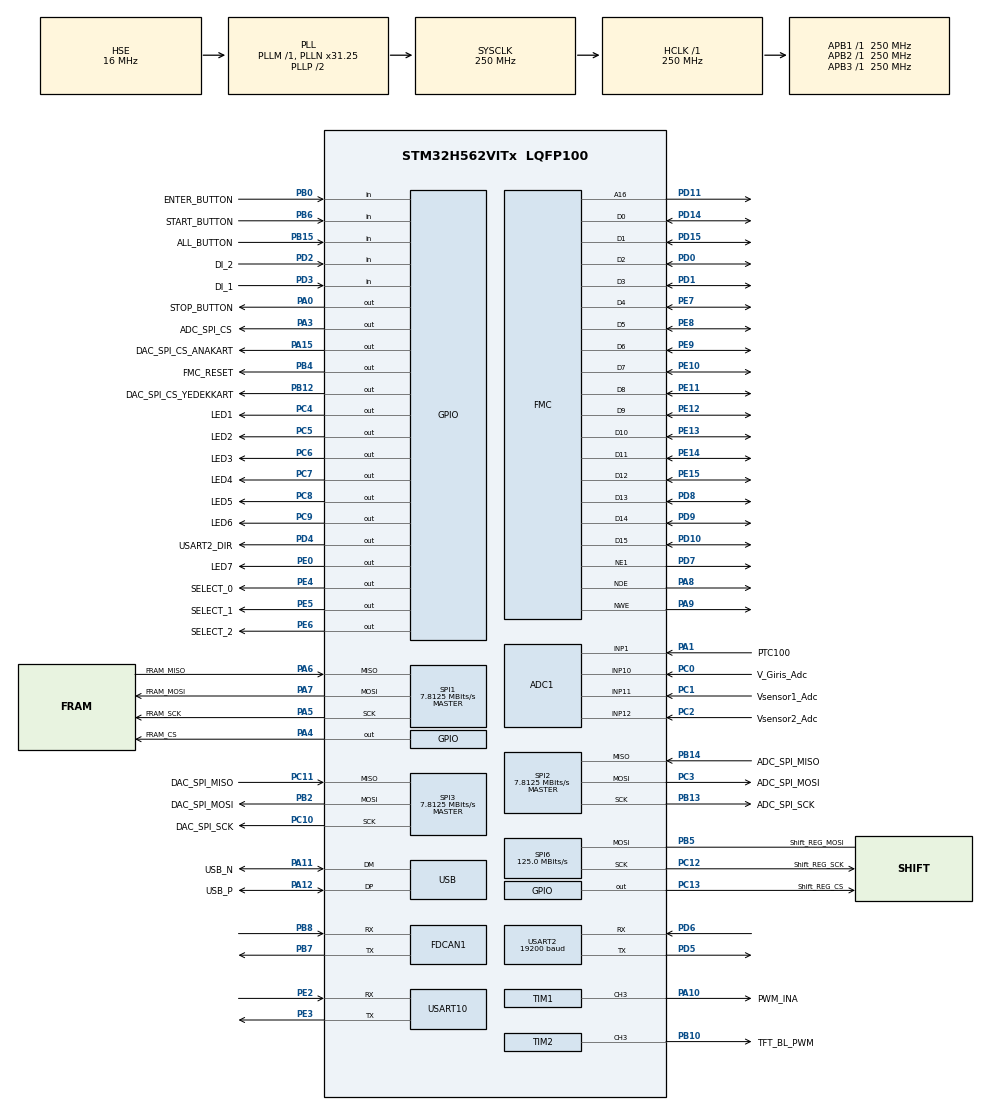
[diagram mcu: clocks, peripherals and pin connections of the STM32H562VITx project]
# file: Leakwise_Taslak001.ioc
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ADC1.Channel-0\#ChannelRegularConversion=ADC_CHANNEL_1
ADC1.MonitoredBy-0\#ChannelRegularConversion=__NULL
ADC1.NbrOfConversionFlag=1
ADC1.OffsetNumber-0\#ChannelRegularConversion=ADC_OFFSET_NONE
ADC1.Rank-0\#ChannelRegularConversion=1
ADC1.SamplingTime-0\#ChannelRegularConversion=ADC_SAMPLETIME_2CYCLES_5
ADC1.master=1
BOOTPATH.BootPathName=LEGACY
BOOTPATH.UserSelectedBootPath=LEGACY
CORTEX_M33_NS.AccessPermission-Cortex_Memory_Protection_Unit_Region0_Settings=MPU_REGION_ALL_RW
CORTEX_M33_NS.BaseAddress-Cortex_Memory_Protection_Unit_Region0_Settings=0x08FFF800
CORTEX_M33_NS.CacheableAttribute-Cortex_Memory_Protection_Unit_Region0_Settings=MPU_NOT_CACHEABLE
CORTEX_M33_NS.DisableExec-Cortex_Memory_Protection_Unit_Region0_Settings=MPU_INSTRUCTION_ACCESS_DISABLE
CORTEX_M33_NS.Enable-Cortex_Memory_Protection_Unit_Region0_Settings=MPU_REGION_ENABLE
CORTEX_M33_NS.LimitAddress-Cortex_Memory_Protection_Unit_Region0_Settings=0x08FFFFFF
CORTEX_M33_NS.MPU_Control=MPU_PRIVILEGED_DEFAULT
CORTEX_M33_NS.userName=CORTEX_M33
FDCAN1.CalculateBaudRateNominal=333333
FDCAN1.CalculateTimeBitNominal=3000
FDCAN1.CalculateTimeQuantumNominal=1000.0
FMC.AddressSetupTime1=10
FMC.BusTurnAroundDuration1=4
FMC.DataHoldTime1=2
FMC.DataSetupTime1=7
FMC.ExtendedMode1=FMC_EXTENDED_MODE_DISABLE
FMC.WriteFifo1=FMC_WRITE_FIFO_DISABLE
FMC.WriteFifo2=FMC_WRITE_FIFO_DISABLE
GPDMA1.DATAHANDLING_GPDMACH5=NONE
GPDMA1.DESTDATAWIDTH_GPDMACH5=DMA_DEST_DATAWIDTH_HALFWORD
GPDMA1.DESTINC_GPDMACH0=DMA_DINC_INCREMENTED
GPDMA1.DESTINC_GPDMACH4=DMA_DINC_INCREMENTED
GPDMA1.DESTINC_GPDMACH5=DMA_DINC_INCREMENTED
GPDMA1.DIRECTION_GPDMACH3=DMA_MEMORY_TO_PERIPH
GPDMA1.IPHANDLE_GPDMACH0-SIMPLEREQUEST_GPDMACH0=__NULL
GPDMA1.IPHANDLE_GPDMACH3-SIMPLEREQUEST_GPDMACH3=__NULL
GPDMA1.IPHANDLE_GPDMACH4-SIMPLEREQUEST_GPDMACH4=__NULL
GPDMA1.PRIORITY_GPDMACH3=DMA_LOW_PRIORITY_HIGH_WEIGHT
GPDMA1.PRIORITY_GPDMACH4=DMA_LOW_PRIORITY_HIGH_WEIGHT
GPDMA1.REQUEST_GPDMACH0=GPDMA1_REQUEST_SPI1_RX
GPDMA1.REQUEST_GPDMACH3=GPDMA1_REQUEST_USART2_TX
GPDMA1.REQUEST_GPDMACH4=GPDMA1_REQUEST_USART2_RX
GPDMA1.SRCDATAWIDTH_GPDMACH5=DMA_SRC_DATAWIDTH_HALFWORD
GPDMA1.SRCINC_GPDMACH3=DMA_SINC_INCREMENTED
GPDMA1.SRCINC_GPDMACH5=DMA_SINC_INCREMENTED
GPDMA2.PRIORITY_LL_GPDMACH6=DMA_LOW_PRIORITY_LOW_WEIGHT
Mcu.Family=STM32H5
Mcu.Name=STM32H562VITx
Mcu.Package=LQFP100
NVIC.GPDMA1_Channel0_IRQn=true\:1\:0\:true\:false\:true\:true\:true\:true\:true
NVIC.GPDMA1_Channel3_IRQn=true\:1\:0\:true\:false\:true\:true\:false\:true\:true
NVIC.GPDMA1_Channel4_IRQn=true\:1\:0\:true\:false\:true\:true\:false\:true\:true
NVIC.GPDMA1_Channel5_IRQn=true\:1\:0\:true\:false\:true\:false\:true\:true\:true
NVIC.GPDMA2_Channel6_IRQn=true\:5\:0\:true\:false\:true\:false\:true\:true\:true
NVIC.PriorityGroup=NVIC_PRIORITYGROUP_4
NVIC.SPI1_IRQn=true\:1\:0\:true\:false\:true\:false\:true\:true\:true
NVIC.TIM3_IRQn=true\:0\:0\:true\:false\:true\:false\:true\:true\:true
NVIC.TIM6_IRQn=true\:15\:0\:false\:false\:true\:false\:false\:true\:true
NVIC.TimeBase=TIM6_IRQn
NVIC.TimeBaseIP=TIM6
NVIC.USART2_IRQn=true\:5\:0\:true\:false\:true\:false\:true\:true\:true
NVIC.USB_DRD_FS_IRQn=true\:1\:0\:true\:false\:true\:false\:true\:true\:true
PA0.GPIO_Label=STOP_BUTTON
PA0.Signal=GPIO_Output
PA1.GPIO_Label=PTC100
PA1.Signal=ADCx_INP1
PA10.GPIO_Label=PWM_INA
PA10.Signal=S_TIM1_CH3
PA11.GPIO_Label=USB_N
PA11.Mode=Device
PA11.Signal=USB_DM
PA12.GPIO_Label=USB_P
PA12.Mode=Device
PA12.Signal=USB_DP
PA13(JTMS/SWDIO).Mode=Trace_Asynchronous_SW
PA13(JTMS/SWDIO).Signal=DEBUG_JTMS-SWDIO
PA14(JTCK/SWCLK).Mode=Trace_Asynchronous_SW
PA14(JTCK/SWCLK).Signal=DEBUG_JTCK-SWCLK
PA15(JTDI).GPIO_Label=DAC_SPI_CS_ANAKART
PA15(JTDI).Signal=GPIO_Output
PA3.GPIO_Label=ADC_SPI_CS
PA3.Signal=GPIO_Output
PA4.GPIO_Label=FRAM_CS
PA4.Signal=GPIO_Output
PA5.GPIO_Label=FRAM_SCK
PA5.Mode=Full_Duplex_Master
PA5.Signal=SPI1_SCK
PA6.GPIO_Label=FRAM_MISO
PA6.Mode=Full_Duplex_Master
PA6.Signal=SPI1_MISO
PA7.GPIO_Label=FRAM_MOSI
PA7.Mode=Full_Duplex_Master
PA7.Signal=SPI1_MOSI
PA8.Signal=FMC_NOE
PA9.Signal=FMC_NWE
PB0.GPIO_Label=ENTER_BUTTON
PB0.GPIO_PuPd=GPIO_PULLDOWN
PB0.Signal=GPIO_Input
PB10.GPIO_Label=TFT_BL_PWM
PB10.Signal=S_TIM2_CH3
PB12.GPIO_Label=DAC_SPI_CS_YEDEKKART
PB12.Signal=GPIO_Output
PB13.GPIO_Label=ADC_SPI_SCK
PB13.Mode=Full_Duplex_Master
PB13.Signal=SPI2_SCK
PB14.GPIO_Label=ADC_SPI_MISO
PB14.Mode=Full_Duplex_Master
PB14.Signal=SPI2_MISO
PB15.GPIO_Label=ALL_BUTTON
PB15.Signal=GPIO_Input
PB2.GPIO_Label=DAC_SPI_MOSI
PB2.Mode=Full_Duplex_Master
PB2.Signal=SPI3_MOSI
PB3(JTDO/TRACESWO).Mode=Trace_Asynchronous_SW
PB3(JTDO/TRACESWO).Signal=DEBUG_JTDO-SWO
PB4(NJTRST).GPIO_Label=FMC_RESET
PB4(NJTRST).Signal=GPIO_Output
PB5.GPIO_Label=Shift_REG_MOSI
PB5.Mode=Simplex_Bidirectional_Master
PB5.Signal=SPI6_MOSI
PB6.GPIO_Label=START_BUTTON
PB6.GPIO_PuPd=GPIO_PULLDOWN
PB6.Signal=GPIO_Input
PB7.Mode=FDCAN_Activate
PB7.Signal=FDCAN1_TX
PB8.Mode=FDCAN_Activate
PB8.Signal=FDCAN1_RX
PC0.GPIO_Label=V_Giris_Adc
PC0.Signal=ADCx_INP10
PC1.GPIO_Label=Vsensor1_Adc
PC1.Signal=ADCx_INP11
PC10.GPIO_Label=DAC_SPI_SCK
PC10.Mode=Full_Duplex_Master
PC10.Signal=SPI3_SCK
PC11.GPIO_Label=DAC_SPI_MISO
PC11.Mode=Full_Duplex_Master
PC11.Signal=SPI3_MISO
PC12.GPIO_Label=Shift_REG_SCK
PC12.Mode=Simplex_Bidirectional_Master
PC12.Signal=SPI6_SCK
PC13.GPIO_Label=Shift_REG_CS
PC13.Signal=GPIO_Output
PC14-OSC32_IN(OSC32_IN).Mode=LSE-External-Oscillator
PC14-OSC32_IN(OSC32_IN).Signal=RCC_OSC32_IN
PC15-OSC32_OUT(OSC32_OUT).Mode=LSE-External-Oscillator
PC15-OSC32_OUT(OSC32_OUT).Signal=RCC_OSC32_OUT
PC2.GPIO_Label=Vsensor2_Adc
PC2.Signal=ADCx_INP12
PC3.GPIO_Label=ADC_SPI_MOSI
PC3.Mode=Full_Duplex_Master
PC3.Signal=SPI2_MOSI
PC4.GPIO_Label=LED1
PC4.Signal=GPIO_Output
PC5.GPIO_Label=LED2
PC5.Signal=GPIO_Output
PC6.GPIO_Label=LED3
PC6.Signal=GPIO_Output
PC7.GPIO_Label=LED4
PC7.Signal=GPIO_Output
PC8.GPIO_Label=LED5
PC8.Signal=GPIO_Output
PC9.GPIO_Label=LED6
PC9.Signal=GPIO_Output
PD0.Signal=FMC_D2_DA2
PD1.Signal=FMC_D3_DA3
PD10.Signal=FMC_D15_DA15
PD11.Signal=FMC_A16_CLE
PD14.Signal=FMC_D0_DA0
PD15.Signal=FMC_D1_DA1
PD2.GPIO_Label=DI_2
PD2.Signal=GPIO_Input
PD3.GPIO_Label=DI_1
PD3.Signal=GPIO_Input
PD4.GPIO_Label=USART2_DIR
PD4.Signal=GPIO_Output
PD5.Mode=Asynchronous
PD5.Signal=USART2_TX
PD6.Mode=Asynchronous
PD6.Signal=USART2_RX
PD7.Mode=NorPsramChipSelect1_1
PD7.Signal=FMC_NE1
PD8.Signal=FMC_D13_DA13
PD9.Signal=FMC_D14_DA14
PE0.GPIO_Label=LED7
PE0.Signal=GPIO_Output
PE10.Signal=FMC_D7_DA7
PE11.Signal=FMC_D8_DA8
PE12.Signal=FMC_D9_DA9
PE13.Signal=FMC_D10_DA10
PE14.Signal=FMC_D11_DA11
PE15.Signal=FMC_D12_DA12
PE2.Mode=Asynchronous
PE2.Signal=USART10_RX
PE3.Mode=Asynchronous
PE3.Signal=USART10_TX
PE4.GPIO_Label=SELECT_0
PE4.Signal=GPIO_Output
PE5.GPIO_Label=SELECT_1
PE5.Signal=GPIO_Output
PE6.GPIO_Label=SELECT_2
PE6.Signal=GPIO_Output
PE7.Signal=FMC_D4_DA4
PE8.Signal=FMC_D5_DA5
PE9.Signal=FMC_D6_DA6
PH0-OSC_IN(PH0).Mode=HSE-External-Oscillator
PH0-OSC_IN(PH0).Signal=RCC_OSC_IN
PH1-OSC_OUT(PH1).Mode=HSE-External-Oscillator
PH1-OSC_OUT(PH1).Signal=RCC_OSC_OUT
ProjectManager.HeapSize=0x200
ProjectManager.StackSize=0x400
ProjectManager.TargetToolchain=STM32CubeIDE
RCC.ADCCLockSelection=RCC_ADCDACCLKSOURCE_PLL2R
RCC.ADCFreq_Value=75000000
RCC.AHBFreq_Value=250000000
RCC.APB1Freq_Value=250000000
RCC.APB1TimFreq_Value=250000000
RCC.APB2Freq_Value=250000000
RCC.APB2TimFreq_Value=250000000
RCC.APB3Freq_Value=250000000
RCC.CSI_VALUE=4000000
RCC.CortexFreq_Value=250000000
RCC.DACLowPowerCLockSelection=RCC_DACLPCLKSOURCE_LSI
RCC.EPOD_VALUE=16000000
RCC.HCLKFreq_Value=250000000
RCC.HSE_VALUE=16000000
RCC.HSI48_VALUE=48000000
RCC.HSI_VALUE=64000000
RCC.LSIRC_VALUE=32000
RCC.PLL2FRACN=3072
RCC.PLL2N=9
RCC.PLL2Source=RCC_PLL2_SOURCE_HSE
RCC.PLLFRACN=2048
RCC.PLLN=31
RCC.PLLSourceVirtual=RCC_PLL1_SOURCE_HSE
RCC.SYSCLKFreq_VALUE=250000000
RCC.SYSCLKSource=RCC_SYSCLKSOURCE_PLLCLK
RCC.USBFreq_Value=48000000
RCC.VCOOutputFreq_Value=500000000
SH.ADCx_INP1.0=ADC1_INP1,IN1-Single-Ended
SH.ADCx_INP10.0=ADC1_INP10,IN10-Single-Ended
SH.ADCx_INP11.0=ADC1_INP11,IN11-Single-Ended
SH.ADCx_INP12.0=ADC1_INP12,IN12-Single-Ended
SH.FMC_A16_CLE.0=FMC_A16,A16_1
SH.FMC_D0_DA0.0=FMC_D0,16b-d1
SH.FMC_D10_DA10.0=FMC_D10,16b-d1
SH.FMC_D11_DA11.0=FMC_D11,16b-d1
SH.FMC_D12_DA12.0=FMC_D12,16b-d1
SH.FMC_D13_DA13.0=FMC_D13,16b-d1
SH.FMC_D14_DA14.0=FMC_D14,16b-d1
SH.FMC_D15_DA15.0=FMC_D15,16b-d1
SH.FMC_D1_DA1.0=FMC_D1,16b-d1
SH.FMC_D2_DA2.0=FMC_D2,16b-d1
SH.FMC_D3_DA3.0=FMC_D3,16b-d1
SH.FMC_D4_DA4.0=FMC_D4,16b-d1
SH.FMC_D5_DA5.0=FMC_D5,16b-d1
SH.FMC_D6_DA6.0=FMC_D6,16b-d1
SH.FMC_D7_DA7.0=FMC_D7,16b-d1
SH.FMC_D8_DA8.0=FMC_D8,16b-d1
SH.FMC_D9_DA9.0=FMC_D9,16b-d1
SH.FMC_NOE.0=FMC_NOE,Lcd1
SH.FMC_NWE.0=FMC_NWE,Lcd1
SH.S_TIM1_CH3.0=TIM1_CH3,Output Compare3 CH3
SH.S_TIM2_CH3.0=TIM2_CH3,PWM Generation3 CH3
SPI1.BaudRatePrescaler=SPI_BAUDRATEPRESCALER_32
SPI1.CalculateBaudRate=7.8125 MBits/s
SPI1.DataSize=SPI_DATASIZE_8BIT
SPI1.Direction=SPI_DIRECTION_2LINES
SPI1.FifoThreshold=SPI_FIFO_THRESHOLD_01DATA
SPI1.Mode=SPI_MODE_MASTER
SPI1.VirtualType=VM_MASTER
SPI2.BaudRatePrescaler=SPI_BAUDRATEPRESCALER_32
SPI2.CalculateBaudRate=7.8125 MBits/s
SPI2.DataSize=SPI_DATASIZE_8BIT
SPI2.Direction=SPI_DIRECTION_2LINES
SPI2.Mode=SPI_MODE_MASTER
SPI2.VirtualType=VM_MASTER
SPI3.BaudRatePrescaler=SPI_BAUDRATEPRESCALER_32
SPI3.CalculateBaudRate=7.8125 MBits/s
SPI3.DataSize=SPI_DATASIZE_8BIT
SPI3.Direction=SPI_DIRECTION_2LINES
SPI3.Mode=SPI_MODE_MASTER
SPI3.VirtualType=VM_MASTER
SPI6.CalculateBaudRate=125.0 MBits/s
SPI6.DataSize=SPI_DATASIZE_16BIT
SPI6.Direction=SPI_DIRECTION_1LINE
SPI6.Mode=SPI_MODE_MASTER
SPI6.VirtualType=VM_MASTER
STMicroelectronics.X-CUBE-FREERTOS.1.1.0.configENABLE_FPU=1
STMicroelectronics.X-CUBE-TOUCHGFX.4.22.1.ApplicationCcGraphicsJjApplication=TouchGFXOoGenerator
STMicroelectronics.X-CUBE-TOUCHGFX.4.22.1.tgfx_app_mem_pool_size=32768
STMicroelectronics.X-CUBE-TOUCHGFX.4.22.1.tgfx_app_stack_size=32640
STMicroelectronics.X-CUBE-TOUCHGFX.4.22.1.tgfx_buffering_strategy=Double
STMicroelectronics.X-CUBE-TOUCHGFX.4.22.1.tgfx_custom_height=240
STMicroelectronics.X-CUBE-TOUCHGFX.4.22.1.tgfx_custom_width=320
STMicroelectronics.X-CUBE-TOUCHGFX.4.22.1.tgfx_display_interface=disp_fmc
STMicroelectronics.X-CUBE-TOUCHGFX.4.22.1.tgfx_hardware_accelerator=dma_none
STMicroelectronics.X-CUBE-TOUCHGFX.4.22.1.tgfx_oswrapper=ThreadX
STMicroelectronics.X-CUBE-TOUCHGFX.4.22.1.tgfx_vector_rendering=Enabled
STMicroelectronics.X-CUBE-TOUCHGFX.4.22.1_IsPackSelfContextualization=true
THREADX.AZRTOS_APP_MEM_ALLOCATION_METHOD=1
THREADX.TX_APP_CREATION=1
THREADX.TX_APP_GENERATE_INIT_CODE=true
THREADX.TX_APP_MEM_POOL_SIZE=65536
THREADX.TX_APP_THREAD_PRIO=9
THREADX.TX_TIMER_TICKS_PER_SECOND=1000
TIM1.Channel-Output\ Compare3\ CH3=TIM_CHANNEL_3
TIM1.PulseNoDither_3=500
TIM2.Channel-PWM\ Generation3\ CH3=TIM_CHANNEL_3
TIM2.PeriodNoDither=25000
TIM2.Prescaler=0
TIM2.PulseNoDither_3=25000
TIM3.AutoReloadPreload=TIM_AUTORELOAD_PRELOAD_ENABLE
TIM3.PeriodNoDither=15259-1
TIM3.Prescaler=1-1
TIM4.AutoReloadPreload=TIM_AUTORELOAD_PRELOAD_ENABLE
TIM4.PeriodNoDither=25000
TIM4.Prescaler=2
TIM4.TIM_MasterOutputTrigger=TIM_TRGO_UPDATE
USART10.VirtualMode=VM_ASYNC
USART2.BaudRate=19200
USART2.MSBFirstParam=ADVFEATURE_MSBFIRST_DISABLE
USART2.OverSampling=UART_OVERSAMPLING_8
USART2.VirtualMode=VM_ASYNC
USB.VirtualMode=Device_Only
VP_BOOTPATH_VS_BOOTPATH.Mode=BP_Activate
VP_CORDIC_VS_CORDIC.Mode=CORDIC_Activate
VP_CORTEX_M33_NS_VS_Hclk.Mode=Hclk_Mode
VP_CRC_VS_CRC.Mode=CRC_Activate
VP_GPDMA1_VS_GPDMACH0.Mode=SIMPLEREQUEST_GPDMACH0
VP_GPDMA1_VS_GPDMACH1.Mode=SIMPLEREQUEST_GPDMACH1
VP_GPDMA1_VS_GPDMACH3.Mode=SIMPLEREQUEST_GPDMACH3
VP_GPDMA1_VS_GPDMACH4.Mode=SIMPLEREQUEST_GPDMACH4
VP_GPDMA1_VS_GPDMACH5.Mode=SIMPLEREQUEST_GPDMACH5
VP_GPDMA2_VS_GPDMACH6.Mode=LINKEDLIST_GPDMACH6
VP_ICACHE_VS_ICACHE.Mode=DirectMappedCache
VP_MEMORYMAP_VS_MEMORYMAP.Mode=CurAppReg
VP_PWR_VS_DBSignals.Mode=DisableDeadBatterySignals
VP_PWR_VS_LPOM.Mode=PowerOptimisation
VP_PWR_VS_SECSignals.Mode=Security/Privilege
VP_RCC_USB.Mode=CRS SYNC Source USB
VP_STMicroelectronics.X-CUBE-TOUCHGFX_VS_GraphicsJjApplication_4.22.1.Mode=GraphicsJjApplication
VP_SYS_VS_tim6.Mode=TIM6
VP_THREADX_VS_RTOSJjThreadXJjCoreJjDefault.Mode=Core_Default
VP_TIM3_VS_ClockSourceINT.Mode=Internal
VP_TIM4_VS_ClockSourceINT.Mode=Internal
board=custom

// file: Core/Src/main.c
/* USER CODE BEGIN Header */
/**
  ******************************************************************************
  * @file           : main.c
  * @brief          : Main program body
  ******************************************************************************
  * @attention
  *
  * Copyright (c) 2024 STMicroelectronics.
  * All rights reserved.
  *
  * This software is licensed under terms that can be found in the LICENSE file
  * in the root directory of this software component.
  * If no LICENSE file comes with this software, it is provided AS-IS.
  *
  ******************************************************************************
  */
/* USER CODE END Header */
#include "app_threadx.h"
#include "main.h"
#include "adc.h"
#include "cordic.h"
#include "crc.h"
#include "fdcan.h"
#include "gpdma.h"
#include "icache.h"
#include "memorymap.h"
#include "spi.h"
#include "tim.h"
#include "usart.h"
#include "usb.h"
#include "gpio.h"
#include "fmc.h"
#include "app_touchgfx.h"

/* USER CODE BEGIN PV */
volatile uint32_t ysf=0;

/* USER CODE END PV */

void SystemClock_Config(void);
static void MPU_Config(void);

int main(void)
{

  /* MCU Configuration--------------------------------------------------------*/

  /* MPU Configuration--------------------------------------------------------*/
  MPU_Config();

  /* Reset of all peripherals, Initializes the Flash interface and the Systick. */
  HAL_Init();

  /* Configure the system clock */
  SystemClock_Config();

  /* Initialize all configured peripherals */
  MX_GPIO_Init();
  MX_GPDMA1_Init();
  MX_GPDMA2_Init();
  MX_ICACHE_Init();
  MX_USB_PCD_Init();
  MX_FDCAN1_Init();
  MX_TIM1_Init();
  MX_TIM4_Init();
  MX_USART2_UART_Init();
  MX_TIM2_Init();
  MX_USART10_UART_Init();
  MX_SPI1_Init();
  MX_CRC_Init();
  MX_FMC_Init();
  MX_TIM3_Init();
  MX_CORDIC_Init();
  MX_ADC1_Init();
  MX_SPI2_Init();
  MX_SPI3_Init();
  MX_SPI6_Init();
  /* Call PreOsInit function */
  MX_TouchGFX_PreOSInit();

  MX_ThreadX_Init();

  /* We should never get here as control is now taken by the scheduler */

  /* Infinite loop */
  while (1)
  {

  }
}

void SystemClock_Config(void)
{
  RCC_OscInitTypeDef RCC_OscInitStruct = {0};
  RCC_ClkInitTypeDef RCC_ClkInitStruct = {0};
  RCC_CRSInitTypeDef RCC_CRSInitStruct = {0};

  /** Configure the main internal regulator output voltage
  */
  __HAL_PWR_VOLTAGESCALING_CONFIG(PWR_REGULATOR_VOLTAGE_SCALE0);

  while(!__HAL_PWR_GET_FLAG(PWR_FLAG_VOSRDY)) {}

  /** Initializes the RCC Oscillators according to the specified parameters
  * in the RCC_OscInitTypeDef structure.
  */
  RCC_OscInitStruct.OscillatorType = RCC_OSCILLATORTYPE_HSI48|RCC_OSCILLATORTYPE_HSE;
  RCC_OscInitStruct.HSEState = RCC_HSE_ON;
  RCC_OscInitStruct.HSI48State = RCC_HSI48_ON;
  RCC_OscInitStruct.PLL.PLLState = RCC_PLL_ON;
  RCC_OscInitStruct.PLL.PLLSource = RCC_PLL1_SOURCE_HSE;
  RCC_OscInitStruct.PLL.PLLM = 1;
  RCC_OscInitStruct.PLL.PLLN = 31;
  RCC_OscInitStruct.PLL.PLLP = 2;
  RCC_OscInitStruct.PLL.PLLQ = 2;
  RCC_OscInitStruct.PLL.PLLR = 2;
  RCC_OscInitStruct.PLL.PLLRGE = RCC_PLL1_VCIRANGE_3;
  RCC_OscInitStruct.PLL.PLLVCOSEL = RCC_PLL1_VCORANGE_WIDE;
  RCC_OscInitStruct.PLL.PLLFRACN = 2048;
  if (HAL_RCC_OscConfig(&RCC_OscInitStruct) != HAL_OK)
  {
    Error_Handler();
  }

  /** Initializes the CPU, AHB and APB buses clocks
  */
  RCC_ClkInitStruct.ClockType = RCC_CLOCKTYPE_HCLK|RCC_CLOCKTYPE_SYSCLK
                              |RCC_CLOCKTYPE_PCLK1|RCC_CLOCKTYPE_PCLK2
                              |RCC_CLOCKTYPE_PCLK3;
  RCC_ClkInitStruct.SYSCLKSource = RCC_SYSCLKSOURCE_PLLCLK;
  RCC_ClkInitStruct.AHBCLKDivider = RCC_SYSCLK_DIV1;
  RCC_ClkInitStruct.APB1CLKDivider = RCC_HCLK_DIV1;
  RCC_ClkInitStruct.APB2CLKDivider = RCC_HCLK_DIV1;
  RCC_ClkInitStruct.APB3CLKDivider = RCC_HCLK_DIV1;

  if (HAL_RCC_ClockConfig(&RCC_ClkInitStruct, FLASH_LATENCY_5) != HAL_OK)
  {
    Error_Handler();
  }

  /** Enable the CRS APB clock
  */
  __HAL_RCC_CRS_CLK_ENABLE();

  /** Configures CRS
  */
  RCC_CRSInitStruct.Prescaler = RCC_CRS_SYNC_DIV1;
  RCC_CRSInitStruct.Source = RCC_CRS_SYNC_SOURCE_USB;
  RCC_CRSInitStruct.Polarity = RCC_CRS_SYNC_POLARITY_RISING;
  RCC_CRSInitStruct.ReloadValue = __HAL_RCC_CRS_RELOADVALUE_CALCULATE(48000000,1000);
  RCC_CRSInitStruct.ErrorLimitValue = 34;
  RCC_CRSInitStruct.HSI48CalibrationValue = 32;

  HAL_RCCEx_CRSConfig(&RCC_CRSInitStruct);
}

 /* MPU Configuration */

void MPU_Config(void)
{
  MPU_Region_InitTypeDef MPU_InitStruct = {0};
  MPU_Attributes_InitTypeDef MPU_AttributesInit = {0};

  /* Disables the MPU */
  HAL_MPU_Disable();

  /** Initializes and configures the Region and the memory to be protected
  */
  MPU_InitStruct.Enable = MPU_REGION_ENABLE;
  MPU_InitStruct.Number = MPU_REGION_NUMBER0;
  MPU_InitStruct.BaseAddress = 0x08FFF800;
  MPU_InitStruct.LimitAddress = 0x08FFFFFF;
  MPU_InitStruct.AttributesIndex = MPU_ATTRIBUTES_NUMBER0;
  MPU_InitStruct.AccessPermission = MPU_REGION_ALL_RW;
  MPU_InitStruct.DisableExec = MPU_INSTRUCTION_ACCESS_DISABLE;
  MPU_InitStruct.IsShareable = MPU_ACCESS_NOT_SHAREABLE;

  HAL_MPU_ConfigRegion(&MPU_InitStruct);
  MPU_AttributesInit.Number = MPU_REGION_NUMBER0;
  MPU_AttributesInit.Attributes = MPU_DEVICE_nGnRnE | MPU_NOT_CACHEABLE
                              | MPU_TRANSIENT | MPU_NO_ALLOCATE;

  HAL_MPU_ConfigMemoryAttributes(&MPU_AttributesInit);
  /* Enables the MPU */
  HAL_MPU_Enable(MPU_PRIVILEGED_DEFAULT);

}

void HAL_TIM_PeriodElapsedCallback(TIM_HandleTypeDef *htim)
{
  if (htim->Instance == TIM6) {
    HAL_IncTick();
  }
}

void Error_Handler(void)
{
  __disable_irq();
  while (1)
  {
  }
}
